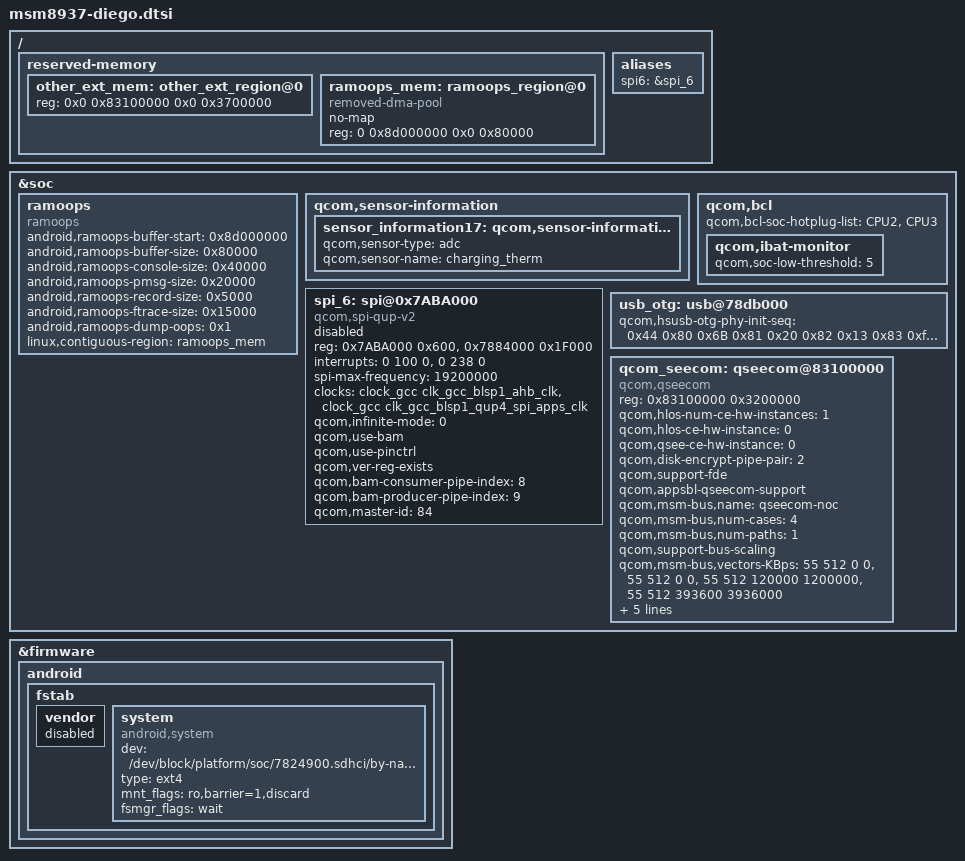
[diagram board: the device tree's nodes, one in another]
/ {
	reserved-memory {
		other_ext_mem: other_ext_region@0 {
			reg = <0x0 0x83100000 0x0 0x3700000>;
		};

		ramoops_mem: ramoops_region@0 {
			compatible = "removed-dma-pool";
			no-map;
			reg = <0 0x8d000000 0x0 0x80000>;
		};
	};

	aliases {
		spi6= &spi_6;
	};
};

&soc {
	ramoops {
		compatible = "ramoops";
		status = "ok";

		/* This is tacked at the end of wcnss_fw_region@0 */
		android,ramoops-buffer-start = <0x8d000000>;
		android,ramoops-buffer-size = <0x80000>;
		android,ramoops-console-size = <0x40000>;
		android,ramoops-pmsg-size = <0x20000>;
		android,ramoops-record-size = <0x5000>;
		android,ramoops-ftrace-size = <0x15000>;
		android,ramoops-dump-oops = <0x1>;
		linux,contiguous-region = <&ramoops_mem>;
	};

	qcom,sensor-information {
		sensor_information17: qcom,sensor-information-17 {
			qcom,sensor-type = "adc";
			qcom,sensor-name = "charging_therm";
		};
	};

	qcom,bcl {
		qcom,bcl-soc-hotplug-list = <&CPU2 &CPU3>;
		qcom,ibat-monitor {
			qcom,soc-low-threshold = <5>;
		};
	};
	
	spi_6: spi@0x7ABA000 { /* BLSP1 QUP6 */
        	compatible = "qcom,spi-qup-v2";
		#address-cells = <1>;
		#size-cells = <0>;
		reg-names = "spi_physical", "spi_bam_physical";
		reg = <0x7ABA000 0x600>,
			<0x7884000 0x1F000>;
		interrupt-names = "spi_irq", "spi_bam_irq";
		interrupts = <0 100 0>, <0 238 0>;
		spi-max-frequency = <19200000>;
		clocks = <&clock_gcc clk_gcc_blsp1_ahb_clk>,
			<&clock_gcc clk_gcc_blsp1_qup4_spi_apps_clk>;
		clock-names = "iface_clk", "core_clk";
		qcom,infinite-mode = <0>;
		qcom,use-bam;
		qcom,use-pinctrl;
		qcom,ver-reg-exists;
		qcom,bam-consumer-pipe-index = <8>;
		qcom,bam-producer-pipe-index = <9>;
		qcom,master-id = <84>;
		status = "disabled";
	};

	usb_otg: usb@78db000 {
		qcom,hsusb-otg-phy-init-seq =
			<0x44 0x80 0x6B 0x81 0x20 0x82 0x13 0x83 0xffffffff>;
	};

	qcom_seecom: qseecom@83100000 {
		compatible = "qcom,qseecom";
		reg = <0x83100000 0x3200000>;
		reg-names = "secapp-region";
		qcom,hlos-num-ce-hw-instances = <1>;
		qcom,hlos-ce-hw-instance = <0>;
		qcom,qsee-ce-hw-instance = <0>;
		qcom,disk-encrypt-pipe-pair = <2>;
		qcom,support-fde;
		qcom,appsbl-qseecom-support;
		qcom,msm-bus,name = "qseecom-noc";
		qcom,msm-bus,num-cases = <4>;
		qcom,msm-bus,num-paths = <1>;
		qcom,support-bus-scaling;
		qcom,msm-bus,vectors-KBps =
			<55 512 0 0>,
			<55 512 0 0>,
			<55 512 120000 1200000>,
			<55 512 393600 3936000>;
		clocks = <&clock_gcc clk_crypto_clk_src>,
			 <&clock_gcc clk_gcc_crypto_clk>,
			 <&clock_gcc clk_gcc_crypto_ahb_clk>,
			 <&clock_gcc clk_gcc_crypto_axi_clk>;
		clock-names = "core_clk_src", "core_clk",
				"iface_clk", "bus_clk";
		qcom,ce-opp-freq = <100000000>;
	};
	/delete-node/ qseecom@85b00000;
};

&firmware {
	android {
		fstab {
			vendor {
				status = "disabled";
			};
			system {
				compatible = "android,system";
				dev = "/dev/block/platform/soc/7824900.sdhci/by-name/system";
				type = "ext4";
				mnt_flags = "ro,barrier=1,discard";
				fsmgr_flags = "wait";
				status = "ok";
			};
		};
	};
};

